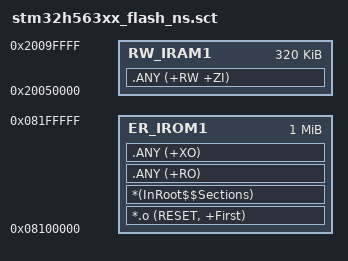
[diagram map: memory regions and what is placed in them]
; *************************************************************
; *** Scatter-Loading Description File generated by uVision ***
; *************************************************************

LR_IROM1 0x08100000 0x00100000  {    ; load region size_region               Memory is divided. Actual start is 0x08000000 and actual length is 2048K
  ER_IROM1 0x08100000 0x00100000  {  ; load address = execution address
   *.o (RESET, +First)
   *(InRoot$$Sections)
   .ANY (+RO)
   .ANY (+XO)
  }
  RW_IRAM1 0x20050000 0x00050000  {  ; RW data                               Memory is divided. Actual start is 0x20000000 and actual length is 640K
   .ANY (+RW +ZI)
  }
}

